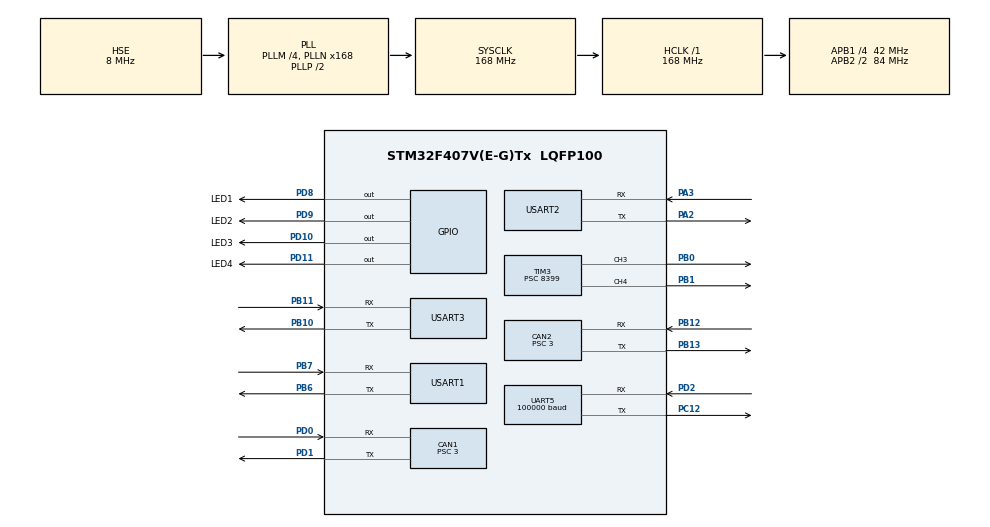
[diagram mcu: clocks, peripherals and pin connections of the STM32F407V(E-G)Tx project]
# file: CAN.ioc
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CAN1.BS1=CAN_BS1_10TQ
CAN1.BS2=CAN_BS2_3TQ
CAN1.CalculateBaudRate=1000000
CAN1.CalculateTimeBit=999.99
CAN1.CalculateTimeQuantum=71.42857142857143
CAN1.Prescaler=3
CAN2.BS1=CAN_BS1_10TQ
CAN2.BS2=CAN_BS2_3TQ
CAN2.CalculateBaudRate=1000000
CAN2.CalculateTimeBit=999.99
CAN2.CalculateTimeQuantum=71.42857142857143
CAN2.Prescaler=3
Dma.Request0=UART5_RX
Dma.Request1=USART2_RX
Dma.UART5_RX.0.Direction=DMA_PERIPH_TO_MEMORY
Dma.UART5_RX.0.FIFOMode=DMA_FIFOMODE_DISABLE
Dma.UART5_RX.0.Instance=DMA1_Stream0
Dma.UART5_RX.0.MemDataAlignment=DMA_MDATAALIGN_BYTE
Dma.UART5_RX.0.MemInc=DMA_MINC_ENABLE
Dma.UART5_RX.0.Mode=DMA_NORMAL
Dma.UART5_RX.0.PeriphDataAlignment=DMA_PDATAALIGN_BYTE
Dma.UART5_RX.0.PeriphInc=DMA_PINC_DISABLE
Dma.UART5_RX.0.Priority=DMA_PRIORITY_LOW
Dma.USART2_RX.1.Direction=DMA_PERIPH_TO_MEMORY
Dma.USART2_RX.1.FIFOMode=DMA_FIFOMODE_DISABLE
Dma.USART2_RX.1.Instance=DMA1_Stream5
Dma.USART2_RX.1.MemDataAlignment=DMA_MDATAALIGN_BYTE
Dma.USART2_RX.1.MemInc=DMA_MINC_ENABLE
Dma.USART2_RX.1.Mode=DMA_NORMAL
Dma.USART2_RX.1.PeriphDataAlignment=DMA_PDATAALIGN_BYTE
Dma.USART2_RX.1.PeriphInc=DMA_PINC_DISABLE
Dma.USART2_RX.1.Priority=DMA_PRIORITY_LOW
FREERTOS.Tasks01=defaultTask,0,128,StartDefaultTask,Default,NULL,Dynamic,NULL,NULL;GIMBAL,0,128,Gimbal_task,As external,NULL,Dynamic,NULL,NULL;DEBUG,0,128,Debug_task,As external,NULL,Dynamic,NULL,NULL;SHOOT,0,128,Shoot_task,As external,NULL,Dynamic,NULL,NULL
Mcu.Family=STM32F4
Mcu.Name=STM32F407V(E-G)Tx
Mcu.Package=LQFP100
NVIC.CAN1_RX0_IRQn=true\:5\:0\:false\:false\:true\:true\:true\:true
NVIC.CAN1_RX1_IRQn=true\:5\:0\:false\:false\:true\:true\:true\:true
NVIC.CAN2_RX0_IRQn=true\:5\:0\:false\:false\:true\:true\:true\:true
NVIC.CAN2_RX1_IRQn=true\:5\:0\:false\:false\:true\:true\:true\:true
NVIC.DMA1_Stream0_IRQn=true\:5\:0\:false\:false\:true\:true\:false\:true
NVIC.DMA1_Stream5_IRQn=true\:5\:0\:false\:false\:true\:true\:false\:true
NVIC.PriorityGroup=NVIC_PRIORITYGROUP_4
NVIC.TIM3_IRQn=true\:5\:0\:false\:false\:true\:true\:true\:true
NVIC.UART5_IRQn=true\:5\:0\:false\:false\:true\:true\:true\:true
NVIC.USART2_IRQn=true\:5\:0\:false\:false\:true\:true\:true\:true
NVIC.USART3_IRQn=true\:5\:0\:false\:false\:true\:true\:true\:true
PA13.Mode=Serial_Wire
PA13.Signal=SYS_JTMS-SWDIO
PA14.Mode=Serial_Wire
PA14.Signal=SYS_JTCK-SWCLK
PA2.Mode=Asynchronous
PA2.Signal=USART2_TX
PA3.Mode=Asynchronous
PA3.Signal=USART2_RX
PB0.Signal=S_TIM3_CH3
PB1.Signal=S_TIM3_CH4
PB10.Mode=Asynchronous
PB10.Signal=USART3_TX
PB11.Mode=Asynchronous
PB11.Signal=USART3_RX
PB12.Mode=CAN_Activate
PB12.Signal=CAN2_RX
PB13.Mode=CAN_Activate
PB13.Signal=CAN2_TX
PB6.Mode=Asynchronous
PB6.Signal=USART1_TX
PB7.Mode=Asynchronous
PB7.Signal=USART1_RX
PC12.Mode=Asynchronous
PC12.Signal=UART5_TX
PD0.Mode=CAN_Activate
PD0.Signal=CAN1_RX
PD1.Mode=CAN_Activate
PD1.Signal=CAN1_TX
PD10.GPIO_Label=LED3
PD10.Signal=GPIO_Output
PD11.GPIO_Label=LED4
PD11.Signal=GPIO_Output
PD2.Mode=Asynchronous
PD2.Signal=UART5_RX
PD8.GPIO_Label=LED1
PD8.Signal=GPIO_Output
PD9.GPIO_Label=LED2
PD9.Signal=GPIO_Output
PH0-OSC_IN.Mode=HSE-External-Oscillator
PH0-OSC_IN.Signal=RCC_OSC_IN
PH1-OSC_OUT.Mode=HSE-External-Oscillator
PH1-OSC_OUT.Signal=RCC_OSC_OUT
ProjectManager.HeapSize=0x200
ProjectManager.StackSize=0x400
ProjectManager.TargetToolchain=MDK-ARM V5.32
RCC.48MHZClocksFreq_Value=84000000
RCC.AHBFreq_Value=168000000
RCC.APB1CLKDivider=RCC_HCLK_DIV4
RCC.APB1Freq_Value=42000000
RCC.APB1TimFreq_Value=84000000
RCC.APB2CLKDivider=RCC_HCLK_DIV2
RCC.APB2Freq_Value=84000000
RCC.APB2TimFreq_Value=168000000
RCC.CortexFreq_Value=168000000
RCC.HCLKFreq_Value=168000000
RCC.HSE_VALUE=8000000
RCC.HSI_VALUE=16000000
RCC.LSE_VALUE=32768
RCC.PLLM=4
RCC.PLLN=168
RCC.PLLSourceVirtual=RCC_PLLSOURCE_HSE
RCC.SYSCLKFreq_VALUE=168000000
RCC.SYSCLKSource=RCC_SYSCLKSOURCE_PLLCLK
RCC.VCOOutputFreq_Value=336000000
SH.S_TIM3_CH3.0=TIM3_CH3,Output Compare3 CH3
SH.S_TIM3_CH4.0=TIM3_CH4,Output Compare4 CH4
TIM2.Period=1000-1
TIM2.Prescaler=84
TIM3.Channel-Output\ Compare3\ CH3=TIM_CHANNEL_3
TIM3.Channel-Output\ Compare4\ CH4=TIM_CHANNEL_4
TIM3.Period=9
TIM3.Prescaler=8399
UART5.BaudRate=100000
UART5.Parity=PARITY_EVEN
UART5.VirtualMode=Asynchronous
USART1.VirtualMode=VM_ASYNC
USART2.VirtualMode=VM_ASYNC
USART3.VirtualMode=VM_ASYNC
VP_FREERTOS_VS_CMSIS_V1.Mode=CMSIS_V1
VP_TIM2_VS_ClockSourceINT.Mode=Internal
VP_TIM3_VS_ClockSourceINT.Mode=Internal
board=custom

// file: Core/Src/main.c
/* USER CODE BEGIN Header */
/**
  ******************************************************************************
  * @file           : main.c
  * @brief          : Main program body
  ******************************************************************************
  * @attention
  *
  * <h2><center>&copy; Copyright (c) 2021 STMicroelectronics.
  * All rights reserved.</center></h2>
  *
  * This software component is licensed by ST under BSD 3-Clause license,
  * the "License"; You may not use this file except in compliance with the
  * License. You may obtain a copy of the License at:
  *                        opensource.org/licenses/BSD-3-Clause
  *
  ******************************************************************************
  */
/* USER CODE END Header */
#include "main.h"
#include "cmsis_os.h"
#include "can.h"
#include "dma.h"
#include "tim.h"
#include "usart.h"
#include "gpio.h"

/* USER CODE BEGIN Includes */
#include "bsp_can.h"
//#include "can_receive.h"
//#include "stdio.h"
//#include "pid.h"
//#include "Filtering.h"
//#include "bsp_rc.h"
#include "bsp_imu.h"
#include "remote_control.h"
//#include "Debug_task.h"
/* USER CODE END Includes */

/* USER CODE BEGIN PD */
//#define M6020_MOTOR_SPEED_PID_MAX_OUT 28000.0f
//#define M6020_MOTOR_SPEED_PID_MAX_IOUT 15000.0f //15000.0f
//#define M6020_MOTOR_ANGLE_PID_MAX_OUT 30.0f
//#define M6020_MOTOR_ANGLE_PID_MAX_IOUT 3.0f
//#define MAX_PID_SHOOT_OUT 13000.0f
//#define MAX_PID_SHOOT_IOUT 2000.0f

//#define lingmindu_y 1
//#define lingmindu_p 0.4
//#define SHOOT_START_FLAG 1
//#define SHOOT_STOP_FLAG 3
//#define REMOTE_CONTROL 2
//#define SHOOT1_CURRENT_DERECTION 1
//#define SHOOT2_CURRENT_DERECTION -1
//#define SHOOT_SPEED 10000
//#define SHOOT_STOP 0
/* USER CODE END PD */

/* USER CODE BEGIN PV */
//const motor_measure_t * moto;
//pid_type_def motor_speed_pid;
//pid_type_def motor_angle_pid;
//pid_type_def motor_speed_pid_p;
//pid_type_def motor_angle_pid_p;
//pid_type_def shoot1_pid_ref,shoot2_pid_ref;
//float My_PID_Speed[3] = {300,1.2,700};//30 1.9 500
//float My_PID_Angle[3] = {2.5,0,10};//0.4 5
//float My_PID_Speed_p[3] = {200,0.05,200};
//float My_PID_Angle_p[3] = {10,0,5};
//fp32 shoot1[3]={10,0,0};
//fp32 shoot2[3]={10,0,0};

//motor_measure_t yaw_data;
//motor_measure_t pitch_data;
//motor_measure_t shoot1_motor_data;
//motor_measure_t shoot2_motor_data;
//extern motor_measure_t motor[8];
//gimbal_data_t wt;
//ADRC_t gyro_ADRC;
/* USER CODE END PV */

void SystemClock_Config(void);
void MX_FREERTOS_Init(void);

/* USER CODE BEGIN 0 */

//uint16_t motor_flag=1;

//float Goal_Speed,Angle=0,Angle_p=0;
//extern RC_ctrl_t rc_ctrl;
////const RC_ctrl_t *shoot_ctrl;
////const RC_ctrl_t *gimbal_ctrl;

//int16_t yaw_control;
//int16_t pitch_control;

//float set1=0,set2=0;
//int16_t num=0;
//float TD2_gyro,TD2_gyro_p;
//float give_shoot1_current;
//float give_shoot2_current;
/* USER CODE END 0 */

int main(void)
{

  /* MCU Configuration--------------------------------------------------------*/

  /* Reset of all peripherals, Initializes the Flash interface and the Systick. */
  HAL_Init();

  /* Configure the system clock */
  SystemClock_Config();

  /* Initialize all configured peripherals */
  MX_GPIO_Init();
  MX_CAN1_Init();
  MX_CAN2_Init();
  MX_TIM2_Init();
  MX_USART1_UART_Init();
  MX_DMA_Init();
  MX_UART5_Init();
  MX_TIM3_Init();
  MX_USART2_UART_Init();
  MX_USART3_UART_Init();
  /* USER CODE BEGIN 2 */
	HAL_TIM_Base_Start_IT(&htim3);
	can_filter_init();
  remote_control_init();
	imu_init();

//	PID_init(&motor_speed_pid, PID_POSITION,My_PID_Speed,M6020_MOTOR_SPEED_PID_MAX_OUT,M6020_MOTOR_SPEED_PID_MAX_IOUT);
//	PID_init(&motor_angle_pid, PID_POSITION,My_PID_Angle,M6020_MOTOR_ANGLE_PID_MAX_OUT,M6020_MOTOR_ANGLE_PID_MAX_IOUT);
//	PID_init(&motor_speed_pid_p,PID_POSITION,My_PID_Speed_p,M6020_MOTOR_SPEED_PID_MAX_OUT,M6020_MOTOR_SPEED_PID_MAX_IOUT);
//	PID_init(&motor_angle_pid_p,PID_POSITION,My_PID_Angle_p,M6020_MOTOR_SPEED_PID_MAX_OUT,M6020_MOTOR_SPEED_PID_MAX_IOUT);
//  PID_init(&shoot1_pid_ref,PID_POSITION,shoot1,MAX_PID_SHOOT_OUT,MAX_PID_SHOOT_IOUT);
//  PID_init(&shoot2_pid_ref,PID_POSITION,shoot2,MAX_PID_SHOOT_OUT,MAX_PID_SHOOT_IOUT);
//	gyro_ADRC.TD2.h = 0.01;
//	gyro_ADRC.TD2.delta = 200;
//	Angle=motor_chassis[4].angle;
//	Angle_p=motor_chassis[5].angle;
  /* USER CODE END 2 */

  /* Call init function for freertos objects (in freertos.c) */
  MX_FREERTOS_Init();
  /* Start scheduler */
  osKernelStart();

  /* We should never get here as control is now taken by the scheduler */
  /* Infinite loop */
  /* USER CODE BEGIN WHILE */
  while (1)
  {
//		get_imu_value(&wt);
//
//		yaw_data= *get_yaw_gimbal_motor_measure_point();
//		pitch_data= *get_pitch_gimbal_motor_measure_point();
//		shoot1_motor_data = *get_shoot_motor_measure_point(0);
//	  shoot2_motor_data = *get_shoot_motor_measure_point(1);
//
//		yaw_control=(float)rc_ctrl.rc.ch[2];
//		pitch_control=(float)rc_ctrl.rc.ch[3];

//		Angle=Angle-yaw_control*lingmindu_y/660.0;
//		Angle_p=Angle_p-pitch_control*lingmindu_p/660.0;
//
//		if(Angle>=180)
//		{
//			Angle=-360+Angle;
//
//		}
//		else if(Angle<-180)
//		{
//			Angle=360+Angle;
//		}
//
//		if(Angle_p>=25)
//		{
//			Angle_p=25;
//		}
//		else if(Angle_p<-10)
//		{
//			Angle_p=-10;
//		}

//		//调试
//		if(motor_flag==1)
//		{
////			set1=5;
//			set2=10;
//		}else{
////			set1=30;
//			set2=-10;
//		}
//

//		TD2_gyro = FAST_TD2(&gyro_ADRC,motor[4].speed_rpm);
//		PID_calc_angle(&motor_angle_pid,motor[4].angle,set1);
//		PID_calc_speed(&motor_speed_pid,TD2_gyro,motor_angle_pid.out);
//		TD2_gyro_p = FAST_TD2(&gyro_ADRC,motor[5].speed_rpm);
//		PID_calc_angle(&motor_angle_pid_p,motor[5].angle,set2);
//		PID_calc_speed(&motor_speed_pid_p,TD2_gyro_p,motor_speed_pid_p.out);
//  	CAN_cmd_gimbal(0,motor_speed_pid_p.out,0,0);
//		printf("%f,%f,%f,%f\n",motor_angle_pid.out,set1,TD2_gyro,motor_chassis[4].angle);
//		printf("%f,%f,%f,%f\n",motor_angle_pid_p.out,set2,TD2_gyro_p,motor_chassis[5].angle);
//		TD2_gyro = FAST_TD2(&gyro_ADRC,motor_chassis[4].speed_rpm);
//		TD2_gyro_p = FAST_TD2(&gyro_ADRC,motor_chassis[5].speed_rpm);
//		PID_calc_angle(&motor_angle_pid,motor_chassis[4].angle,Angle);
//		PID_calc_speed(&motor_speed_pid,TD2_gyro,motor_angle_pid.out);
//		PID_calc_angle(&motor_angle_pid_p,motor_chassis[5].angle,Angle_p);
//		PID_calc_speed(&motor_speed_pid_p,TD2_gyro_p,motor_angle_pid_p.out);
//  	CAN_cmd_gimbal(motor_speed_pid.out,motor_speed_pid_p.out,0,0);			//5678
//		CAN_cmd_gimbal(2000,4000,0,0);

//	if(rc_ctrl.rc.s[0]==2)//右下档——无力
//	{
//		CAN_cmd_gimbal(0,0,0,0);
//	}
//	if(rc_ctrl.rc.s[0]==3)//右中挡——遥控控制
//	{
//		   TD2_gyro = FAST_TD2(&gyro_ADRC,wt.v_yaw/10.0);
//		   TD2_gyro_p = FAST_TD2(&gyro_ADRC,wt.v_pitch/10.0);
//		   PID_calc_angle(&motor_angle_pid,wt.p_yaw,Angle);
//		   PID_calc_speed(&motor_speed_pid,TD2_gyro,motor_angle_pid.out);
//		   PID_calc_angle(&motor_angle_pid_p,wt.p_pitch,Angle_p);
//		   PID_calc_speed(&motor_speed_pid_p,TD2_gyro_p,motor_angle_pid_p.out);
//		   CAN_cmd_gimbal(-motor_speed_pid.out,motor_speed_pid_p.out,0,0);			//5678
//		   U1Printf("%f,%f\n",TD2_gyro,wt.v_yaw/10.0);
//
//		switch(rc_ctrl.rc.s[1])
//		{
//			case REMOTE_CONTROL://2

//       break;
//			case SHOOT_START_FLAG://1
//				give_shoot1_current = SHOOT1_CURRENT_DERECTION*PID_calc_speed(&shoot1_pid_ref,motor[6].speed_rpm,SHOOT_SPEED);
//				give_shoot2_current = SHOOT2_CURRENT_DERECTION*PID_calc_speed(&shoot2_pid_ref,-motor[7].speed_rpm,SHOOT_SPEED);
//			  CAN_cmd_shoot(give_shoot1_current,give_shoot2_current);
//				break;
//			case SHOOT_STOP_FLAG://3
//				give_shoot1_current = PID_calc_speed(&shoot1_pid_ref,motor[6].speed_rpm,SHOOT_STOP);
//				give_shoot2_current = PID_calc_speed(&shoot2_pid_ref,motor[7].speed_rpm,SHOOT_STOP);
//			  CAN_cmd_shoot(give_shoot1_current,give_shoot2_current);
//			break;
//		}
//
//	}
//
//	HAL_Delay(5);
}

    /* USER CODE END WHILE */

  }

void SystemClock_Config(void)
{
  RCC_OscInitTypeDef RCC_OscInitStruct = {0};
  RCC_ClkInitTypeDef RCC_ClkInitStruct = {0};

  /** Configure the main internal regulator output voltage
  */
  __HAL_RCC_PWR_CLK_ENABLE();
  __HAL_PWR_VOLTAGESCALING_CONFIG(PWR_REGULATOR_VOLTAGE_SCALE1);
  /** Initializes the RCC Oscillators according to the specified parameters
  * in the RCC_OscInitTypeDef structure.
  */
  RCC_OscInitStruct.OscillatorType = RCC_OSCILLATORTYPE_HSE;
  RCC_OscInitStruct.HSEState = RCC_HSE_ON;
  RCC_OscInitStruct.PLL.PLLState = RCC_PLL_ON;
  RCC_OscInitStruct.PLL.PLLSource = RCC_PLLSOURCE_HSE;
  RCC_OscInitStruct.PLL.PLLM = 4;
  RCC_OscInitStruct.PLL.PLLN = 168;
  RCC_OscInitStruct.PLL.PLLP = RCC_PLLP_DIV2;
  RCC_OscInitStruct.PLL.PLLQ = 4;
  if (HAL_RCC_OscConfig(&RCC_OscInitStruct) != HAL_OK)
  {
    Error_Handler();
  }
  /** Initializes the CPU, AHB and APB buses clocks
  */
  RCC_ClkInitStruct.ClockType = RCC_CLOCKTYPE_HCLK|RCC_CLOCKTYPE_SYSCLK
                              |RCC_CLOCKTYPE_PCLK1|RCC_CLOCKTYPE_PCLK2;
  RCC_ClkInitStruct.SYSCLKSource = RCC_SYSCLKSOURCE_PLLCLK;
  RCC_ClkInitStruct.AHBCLKDivider = RCC_SYSCLK_DIV1;
  RCC_ClkInitStruct.APB1CLKDivider = RCC_HCLK_DIV4;
  RCC_ClkInitStruct.APB2CLKDivider = RCC_HCLK_DIV2;

  if (HAL_RCC_ClockConfig(&RCC_ClkInitStruct, FLASH_LATENCY_5) != HAL_OK)
  {
    Error_Handler();
  }
}

/* USER CODE BEGIN 4 */

//void HAL_TIM_PeriodElapsedCallback(TIM_HandleTypeDef *htim)
//{
//		if(htim==&htim3)
//		{
//			num++;
//			if(num==4000)
//			{
//				motor_flag=-motor_flag;
//				num=0;
//			}
//		}
//}

/* USER CODE END 4 */

void Error_Handler(void)
{
  __disable_irq();
  while (1)
  {
  }
}

/************************ (C) COPYRIGHT STMicroelectronics *****END OF FILE****/

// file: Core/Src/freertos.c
/* USER CODE BEGIN Header */
/**
  ******************************************************************************
  * File Name          : freertos.c
  * Description        : Code for freertos applications
  ******************************************************************************
  * @attention
  *
  * <h2><center>&copy; Copyright (c) 2021 STMicroelectronics.
  * All rights reserved.</center></h2>
  *
  * This software component is licensed by ST under Ultimate Liberty license
  * SLA0044, the "License"; You may not use this file except in compliance with
  * the License. You may obtain a copy of the License at:
  *                             www.st.com/SLA0044
  *
  ******************************************************************************
  */
/* USER CODE END Header */

#include "FreeRTOS.h"
#include "task.h"
#include "main.h"
#include "cmsis_os.h"

osThreadId defaultTaskHandle;
osThreadId GIMBALHandle;
osThreadId DEBUGHandle;
osThreadId SHOOTHandle;

void StartDefaultTask(void const * argument);
extern void Gimbal_task(void const * argument);
extern void Debug_task(void const * argument);
extern void Shoot_task(void const * argument);

void MX_FREERTOS_Init(void); /* (MISRA C 2004 rule 8.1) */

/* GetIdleTaskMemory prototype (linked to static allocation support) */
void vApplicationGetIdleTaskMemory( StaticTask_t **ppxIdleTaskTCBBuffer, StackType_t **ppxIdleTaskStackBuffer, uint32_t *pulIdleTaskStackSize );

/* USER CODE BEGIN GET_IDLE_TASK_MEMORY */
static StaticTask_t xIdleTaskTCBBuffer;
static StackType_t xIdleStack[configMINIMAL_STACK_SIZE];

void vApplicationGetIdleTaskMemory( StaticTask_t **ppxIdleTaskTCBBuffer, StackType_t **ppxIdleTaskStackBuffer, uint32_t *pulIdleTaskStackSize )
{
  *ppxIdleTaskTCBBuffer = &xIdleTaskTCBBuffer;
  *ppxIdleTaskStackBuffer = &xIdleStack[0];
  *pulIdleTaskStackSize = configMINIMAL_STACK_SIZE;
  /* place for user code */
}
/* USER CODE END GET_IDLE_TASK_MEMORY */

void MX_FREERTOS_Init(void) {

  /* Create the thread(s) */
  /* definition and creation of defaultTask */
  osThreadDef(defaultTask, StartDefaultTask, osPriorityNormal, 0, 128);
  defaultTaskHandle = osThreadCreate(osThread(defaultTask), NULL);

  /* definition and creation of GIMBAL */
  osThreadDef(GIMBAL, Gimbal_task, osPriorityNormal, 0, 128);
  GIMBALHandle = osThreadCreate(osThread(GIMBAL), NULL);

  /* definition and creation of DEBUG */
  osThreadDef(DEBUG, Debug_task, osPriorityNormal, 0, 128);
  DEBUGHandle = osThreadCreate(osThread(DEBUG), NULL);

  /* definition and creation of SHOOT */
  osThreadDef(SHOOT, Shoot_task, osPriorityNormal, 0, 128);
  SHOOTHandle = osThreadCreate(osThread(SHOOT), NULL);

}

void StartDefaultTask(void const * argument)
{
  for(;;)
  {
    osDelay(1);
  }
}

/************************ (C) COPYRIGHT STMicroelectronics *****END OF FILE****/
